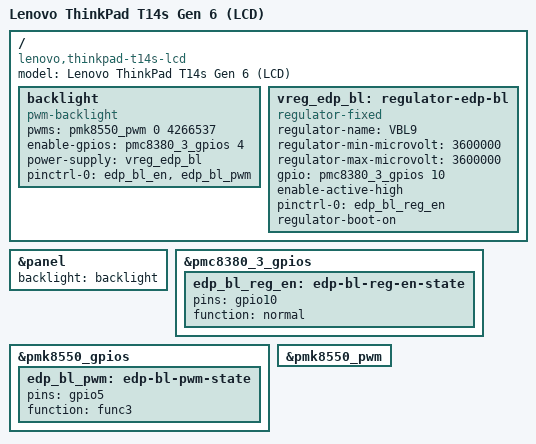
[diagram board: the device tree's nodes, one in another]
// SPDX-License-Identifier: BSD-3-Clause
/*
 * Copyright (c) 2025, Linaro Limited
 */

#include "x1e78100-lenovo-thinkpad-t14s.dtsi"

/ {
	model = "Lenovo ThinkPad T14s Gen 6 (LCD)";
	compatible = "lenovo,thinkpad-t14s-lcd", "lenovo,thinkpad-t14s",
		     "qcom,x1e78100", "qcom,x1e80100";

	backlight: backlight {
		compatible = "pwm-backlight";
		pwms = <&pmk8550_pwm 0 4266537>;
		enable-gpios = <&pmc8380_3_gpios 4 GPIO_ACTIVE_HIGH>;
		power-supply = <&vreg_edp_bl>;

		pinctrl-0 = <&edp_bl_en>, <&edp_bl_pwm>;
		pinctrl-names = "default";
	};

	vreg_edp_bl: regulator-edp-bl {
		compatible = "regulator-fixed";

		regulator-name = "VBL9";
		regulator-min-microvolt = <3600000>;
		regulator-max-microvolt = <3600000>;

		gpio = <&pmc8380_3_gpios 10 GPIO_ACTIVE_HIGH>;
		enable-active-high;

		pinctrl-names = "default";
		pinctrl-0 = <&edp_bl_reg_en>;

		regulator-boot-on;
	};
};

&panel {
	backlight = <&backlight>;
};

&pmc8380_3_gpios {
	edp_bl_reg_en: edp-bl-reg-en-state {
		pins = "gpio10";
		function = "normal";
	};
};

&pmk8550_gpios {
	edp_bl_pwm: edp-bl-pwm-state {
		pins = "gpio5";
		function = "func3";
	};
};

&pmk8550_pwm {
	status = "okay";
};
